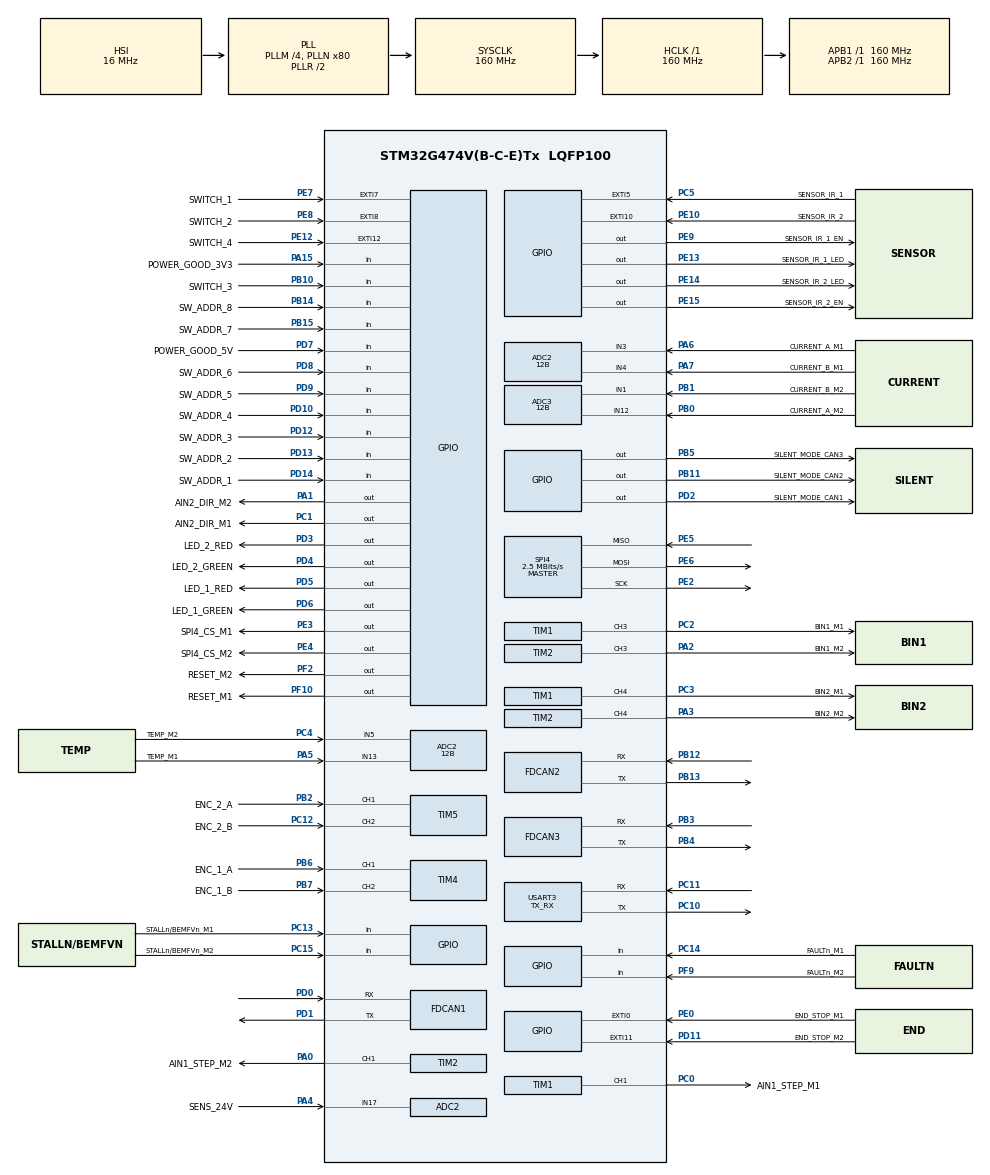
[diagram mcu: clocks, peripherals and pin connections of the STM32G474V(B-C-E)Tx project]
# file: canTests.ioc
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ADC2.Channel-0\#ChannelRegularConversion=ADC_CHANNEL_5
ADC2.Channel-1\#ChannelRegularConversion=ADC_CHANNEL_3
ADC2.Channel-IN13=ADC_CHANNEL_13
ADC2.Channel-IN17=ADC_CHANNEL_17
ADC2.Channel-IN3=ADC_CHANNEL_3
ADC2.Channel-IN5=ADC_CHANNEL_5
ADC2.ClockPrescaler=ADC_CLOCK_ASYNC_DIV1
ADC2.ContinuousConvMode=DISABLE
ADC2.DMAContinuousRequests=DISABLE
ADC2.DataAlign=ADC_DATAALIGN_RIGHT
ADC2.DiscontinuousConvMode=DISABLE
ADC2.EOCSelection=ADC_EOC_SINGLE_CONV
ADC2.EnableAnalogWatchDog1=false
ADC2.EnableAnalogWatchDog2=false
ADC2.EnableAnalogWatchDog3=false
ADC2.EnableInjectedConversion=DISABLE
ADC2.EnableRegularConversion=ENABLE
ADC2.ExternalTrigConv=ADC_SOFTWARE_START
ADC2.ExternalTrigConvEdge=ADC_EXTERNALTRIGCONVEDGE_NONE
ADC2.GainCompensation=0
ADC2.LowPowerAutoWait=DISABLE
ADC2.Mode=ADC_MODE_INDEPENDENT
ADC2.NbrOfConversion=1
ADC2.NbrOfConversionFlag=1
ADC2.OffsetNumber-0\#ChannelRegularConversion=ADC_OFFSET_NONE
ADC2.OffsetNumber-1\#ChannelRegularConversion=ADC_OFFSET_NONE
ADC2.Overrun=ADC_OVR_DATA_PRESERVED
ADC2.OversamplingMode=DISABLE
ADC2.Rank-0\#ChannelRegularConversion=1
ADC2.Rank-1\#ChannelRegularConversion=1
ADC2.Resolution=ADC_RESOLUTION_12B
ADC2.SamplingTime-0\#ChannelRegularConversion=ADC_SAMPLETIME_2CYCLES_5
ADC2.SamplingTime-1\#ChannelRegularConversion=ADC_SAMPLETIME_2CYCLES_5
ADC2.ScanConvMode=ADC_SCAN_DISABLE
ADC2.SingleDiff-1\#ChannelRegularConversion=ADC_DIFFERENTIAL_ENDED
ADC3.Channel-0\#ChannelRegularConversion=ADC_CHANNEL_1
ADC3.Channel-1\#ChannelRegularConversion=ADC_CHANNEL_1
ADC3.ClockPrescaler=ADC_CLOCK_ASYNC_DIV1
ADC3.ContinuousConvMode=DISABLE
ADC3.DMAContinuousRequests=DISABLE
ADC3.DataAlign=ADC_DATAALIGN_RIGHT
ADC3.DiscontinuousConvMode=DISABLE
ADC3.EOCSelection=ADC_EOC_SINGLE_CONV
ADC3.EnableAnalogWatchDog1=false
ADC3.EnableAnalogWatchDog2=false
ADC3.EnableAnalogWatchDog3=false
ADC3.EnableInjectedConversion=DISABLE
ADC3.EnableRegularConversion=ENABLE
ADC3.ExternalTrigConv=ADC_SOFTWARE_START
ADC3.ExternalTrigConvEdge=ADC_EXTERNALTRIGCONVEDGE_NONE
ADC3.GainCompensation=0
ADC3.LowPowerAutoWait=DISABLE
ADC3.Mode=ADC_MODE_INDEPENDENT
ADC3.NbrOfConversion=1
ADC3.NbrOfConversionFlag=1
ADC3.OffsetNumber-0\#ChannelRegularConversion=ADC_OFFSET_NONE
ADC3.OffsetNumber-1\#ChannelRegularConversion=ADC_OFFSET_NONE
ADC3.Overrun=ADC_OVR_DATA_PRESERVED
ADC3.OversamplingMode=DISABLE
ADC3.Rank-0\#ChannelRegularConversion=1
ADC3.Rank-1\#ChannelRegularConversion=1
ADC3.Resolution=ADC_RESOLUTION_12B
ADC3.SamplingTime-0\#ChannelRegularConversion=ADC_SAMPLETIME_2CYCLES_5
ADC3.SamplingTime-1\#ChannelRegularConversion=ADC_SAMPLETIME_2CYCLES_5
ADC3.ScanConvMode=ADC_SCAN_DISABLE
ADC3.master=1
FDCAN1.AutoRetransmission=ENABLE
FDCAN1.ClockDivider=FDCAN_CLOCK_DIV2
FDCAN1.DataPrescaler=2
FDCAN1.DataSyncJumpWidth=4
FDCAN1.DataTimeSeg1=5
FDCAN1.DataTimeSeg2=4
FDCAN1.ExtFiltersNbr=0
FDCAN1.FrameFormat=FDCAN_FRAME_FD_NO_BRS
FDCAN1.Mode=FDCAN_MODE_NORMAL
FDCAN1.NominalPrescaler=2
FDCAN1.NominalSyncJumpWidth=16
FDCAN1.NominalTimeSeg1=63
FDCAN1.NominalTimeSeg2=16
FDCAN1.ProtocolException=DISABLE
FDCAN1.StdFiltersNbr=1
FDCAN1.TransmitPause=ENABLE
FDCAN1.TxFifoQueueMode=FDCAN_TX_FIFO_OPERATION
FDCAN2.AutoRetransmission=ENABLE
FDCAN2.DataPrescaler=1
FDCAN2.DataSyncJumpWidth=4
FDCAN2.DataTimeSeg1=5
FDCAN2.DataTimeSeg2=4
FDCAN2.ExtFiltersNbr=0
FDCAN2.FrameFormat=FDCAN_FRAME_FD_NO_BRS
FDCAN2.Mode=FDCAN_MODE_NORMAL
FDCAN2.NominalPrescaler=1
FDCAN2.NominalSyncJumpWidth=16
FDCAN2.NominalTimeSeg1=63
FDCAN2.NominalTimeSeg2=16
FDCAN2.ProtocolException=DISABLE
FDCAN2.StdFiltersNbr=1
FDCAN2.TransmitPause=ENABLE
FDCAN2.TxFifoQueueMode=FDCAN_TX_FIFO_OPERATION
FDCAN3.AutoRetransmission=ENABLE
FDCAN3.DataPrescaler=1
FDCAN3.DataSyncJumpWidth=4
FDCAN3.DataTimeSeg1=5
FDCAN3.DataTimeSeg2=4
FDCAN3.ExtFiltersNbr=0
FDCAN3.FrameFormat=FDCAN_FRAME_FD_NO_BRS
FDCAN3.Mode=FDCAN_MODE_NORMAL
FDCAN3.NominalPrescaler=1
FDCAN3.NominalSyncJumpWidth=16
FDCAN3.NominalTimeSeg1=63
FDCAN3.NominalTimeSeg2=16
FDCAN3.ProtocolException=DISABLE
FDCAN3.StdFiltersNbr=1
FDCAN3.TransmitPause=ENABLE
FDCAN3.TxFifoQueueMode=FDCAN_TX_FIFO_OPERATION
Mcu.Family=STM32G4
Mcu.Name=STM32G474V(B-C-E)Tx
Mcu.Package=LQFP100
Mcu.UserConstants=APB1_TIMER_CLOCK_FREQUENCY,160000000;CONSOLE_BAUDERATE,115200;SCHEDULER_TIM_PRESCALER,APB1_TIMER_CLOCK_FREQUENCY/1000000;SCHEDULER_TIM_COUNTER_PERIOD,100;ADC_SAMPLING_TIM_PRESCALER,68;ADC_SAMPLING_TIM_COUNTER_PERIOD,100;MOTOR_PWM_TIM_PRESCALER,APB1_TIMER_CLOCK_FREQUENCY/100000;MOTOR_PWM_TIM_COUNTER_PERIOD,100;MOTOR_ACCEL_TIM_PRESCALER,APB1_TIMER_CLOCK_FREQUENCY/100000;MOTOR_ACCEL_TIM_COUNTER_PERIOD,10;MOTOR_ENCODER_TIM_PRESCALER,2;MOTOR_ENCODER_TIM_COUNTER_PERIOD,65534;TEC_TIM_PRESCALER,79;TEC_TIM_COUNTER_PERIOD,65534;FAIL,0;OK,1;FALSE,0;TRUE,1
NVIC.ADC1_2_IRQn=true\:0\:0\:false\:false\:true\:true\:true
NVIC.EXTI0_IRQn=true\:0\:0\:false\:false\:true\:true\:true
NVIC.EXTI15_10_IRQn=true\:0\:0\:false\:false\:true\:true\:true
NVIC.EXTI9_5_IRQn=true\:0\:0\:false\:false\:true\:true\:true
NVIC.PriorityGroup=NVIC_PRIORITYGROUP_4
NVIC.TIM1_BRK_TIM15_IRQn=true\:0\:0\:false\:false\:true\:true\:true
NVIC.TIM1_UP_TIM16_IRQn=true\:0\:0\:false\:false\:true\:true\:true
NVIC.TIM2_IRQn=true\:0\:0\:false\:false\:true\:true\:true
NVIC.TIM3_IRQn=true\:0\:0\:false\:false\:true\:true\:true
NVIC.TIM4_IRQn=true\:0\:0\:false\:false\:true\:true\:true
NVIC.TIM6_DAC_IRQn=true\:0\:0\:false\:false\:true\:true\:true
NVIC.TIM7_DAC_IRQn=true\:0\:0\:false\:false\:true\:true\:true
NVIC.USART3_IRQn=true\:0\:0\:false\:false\:true\:true\:true
PA0.GPIO_Label=AIN1_STEP_M2
PA0.Signal=S_TIM2_CH1
PA1.GPIO_Label=AIN2_DIR_M2
PA1.Signal=GPIO_Output
PA13.Mode=Serial_Wire
PA13.Signal=SYS_JTMS-SWDIO
PA14.Mode=Serial_Wire
PA14.Signal=SYS_JTCK-SWCLK
PA15.GPIO_Label=POWER_GOOD_3V3
PA15.Signal=GPIO_Input
PA2.GPIO_Label=BIN1_M2
PA2.Signal=S_TIM2_CH3
PA3.GPIO_Label=BIN2_M2
PA3.Signal=S_TIM2_CH4
PA4.GPIO_Label=SENS_24V
PA4.Mode=IN17-Single-Ended
PA4.Signal=ADC2_IN17
PA5.GPIO_Label=TEMP_M1
PA5.Mode=IN13-Single-Ended
PA5.Signal=ADC2_IN13
PA6.GPIO_Label=CURRENT_A_M1
PA6.Mode=IN3-Differential
PA6.Signal=ADC2_IN3
PA7.GPIO_Label=CURRENT_B_M1
PA7.Mode=IN3-Differential
PA7.Signal=ADC2_IN4
PB0.GPIO_Label=CURRENT_A_M2
PB0.Mode=IN12-Single-Ended
PB0.Signal=ADC3_IN12
PB1.GPIO_Label=CURRENT_B_M2
PB1.Mode=IN1-Single-Ended
PB1.Signal=ADC3_IN1
PB10.GPIO_Label=SWITCH_3
PB10.Signal=GPIO_Input
PB11.GPIO_Label=SILENT_MODE_CAN2
PB11.Signal=GPIO_Output
PB12.Mode=FDCANFD
PB12.Signal=FDCAN2_RX
PB13.Mode=FDCANFD
PB13.Signal=FDCAN2_TX
PB14.GPIO_Label=SW_ADDR_8
PB14.GPIO_PuPd=GPIO_PULLDOWN
PB14.Signal=GPIO_Input
PB15.GPIO_Label=SW_ADDR_7
PB15.GPIO_PuPd=GPIO_PULLDOWN
PB15.Signal=GPIO_Input
PB2.GPIO_Label=ENC_2_A
PB2.GPIO_PuPd=GPIO_PULLUP
PB2.Signal=S_TIM5_CH1
PB3.Mode=FDCANFD
PB3.Signal=FDCAN3_RX
PB4.Mode=FDCANFD
PB4.Signal=FDCAN3_TX
PB5.GPIO_Label=SILENT_MODE_CAN3
PB5.Signal=GPIO_Output
PB6.GPIO_FM6=SYSCFG_FASTMODEPLUS_PB6
PB6.GPIO_Label=ENC_1_A
PB6.GPIO_PuPd=GPIO_PULLUP
PB6.GPIO_Speed=GPIO_SPEED_FREQ_VERY_HIGH
PB6.Signal=S_TIM4_CH1
PB7.GPIO_FM7=SYSCFG_FASTMODEPLUS_PB7
PB7.GPIO_Label=ENC_1_B
PB7.GPIO_PuPd=GPIO_PULLUP
PB7.GPIO_Speed=GPIO_SPEED_FREQ_VERY_HIGH
PB7.Signal=S_TIM4_CH2
PC0.GPIO_Label=AIN1_STEP_M1
PC0.Signal=S_TIM1_CH1
PC1.GPIO_Label=AIN2_DIR_M1
PC1.Signal=GPIO_Output
PC10.Mode=Asynchronous
PC10.Signal=USART3_TX
PC11.Mode=Asynchronous
PC11.Signal=USART3_RX
PC12.GPIO_Label=ENC_2_B
PC12.GPIO_PuPd=GPIO_PULLUP
PC12.Signal=S_TIM5_CH2
PC13.GPIO_Label=STALLn/BEMFVn_M1
PC13.Signal=GPIO_Input
PC14-OSC32_IN.GPIO_Label=FAULTn_M1
PC14-OSC32_IN.Signal=GPIO_Input
PC15-OSC32_OUT.GPIO_Label=STALLn/BEMFVn_M2
PC15-OSC32_OUT.Signal=GPIO_Input
PC2.GPIO_Label=BIN1_M1
PC2.Signal=S_TIM1_CH3
PC3.GPIO_Label=BIN2_M1
PC3.Signal=S_TIM1_CH4
PC4.GPIO_Label=TEMP_M2
PC4.Mode=IN5-Single-Ended
PC4.Signal=ADC2_IN5
PC5.GPIO_Label=SENSOR_IR_1
PC5.GPIO_ModeDefaultEXTI=GPIO_MODE_IT_RISING_FALLING
PC5.GPIO_PuPd=GPIO_PULLDOWN
PC5.Signal=GPXTI5
PD0.Mode=FDCANFD
PD0.Signal=FDCAN1_RX
PD1.Mode=FDCANFD
PD1.Signal=FDCAN1_TX
PD10.GPIO_Label=SW_ADDR_4
PD10.GPIO_PuPd=GPIO_PULLDOWN
PD10.Signal=GPIO_Input
PD11.GPIO_Label=END_STOP_M2
PD11.GPIO_ModeDefaultEXTI=GPIO_MODE_IT_FALLING
PD11.Signal=GPXTI11
PD12.GPIO_Label=SW_ADDR_3
PD12.GPIO_PuPd=GPIO_PULLDOWN
PD12.Signal=GPIO_Input
PD13.GPIO_Label=SW_ADDR_2
PD13.GPIO_PuPd=GPIO_PULLDOWN
PD13.Signal=GPIO_Input
PD14.GPIO_Label=SW_ADDR_1
PD14.GPIO_PuPd=GPIO_PULLDOWN
PD14.Signal=GPIO_Input
PD2.GPIO_Label=SILENT_MODE_CAN1
PD2.Signal=GPIO_Output
PD3.GPIO_Label=LED_2_RED
PD3.Signal=GPIO_Output
PD4.GPIO_Label=LED_2_GREEN
PD4.Signal=GPIO_Output
PD5.GPIO_Label=LED_1_RED
PD5.Signal=GPIO_Output
PD6.GPIO_Label=LED_1_GREEN
PD6.Signal=GPIO_Output
PD7.GPIO_Label=POWER_GOOD_5V
PD7.Signal=GPIO_Input
PD8.GPIO_Label=SW_ADDR_6
PD8.GPIO_PuPd=GPIO_PULLDOWN
PD8.Signal=GPIO_Input
PD9.GPIO_Label=SW_ADDR_5
PD9.GPIO_PuPd=GPIO_PULLDOWN
PD9.Signal=GPIO_Input
PE0.GPIO_Label=END_STOP_M1
PE0.GPIO_ModeDefaultEXTI=GPIO_MODE_IT_FALLING
PE0.Signal=GPXTI0
PE10.GPIO_Label=SENSOR_IR_2
PE10.GPIO_ModeDefaultEXTI=GPIO_MODE_IT_RISING_FALLING
PE10.GPIO_PuPd=GPIO_PULLDOWN
PE10.Signal=GPXTI10
PE12.GPIO_Label=SWITCH_4
PE12.GPIO_ModeDefaultEXTI=GPIO_MODE_IT_FALLING
PE12.Signal=GPXTI12
PE13.GPIO_Label=SENSOR_IR_1_LED
PE13.Signal=GPIO_Output
PE14.GPIO_Label=SENSOR_IR_2_LED
PE14.Signal=GPIO_Output
PE15.GPIO_Label=SENSOR_IR_2_EN
PE15.Signal=GPIO_Output
PE2.Mode=Full_Duplex_Master
PE2.Signal=SPI4_SCK
PE3.GPIO_Label=SPI4_CS_M1
PE3.Signal=GPIO_Output
PE4.GPIO_Label=SPI4_CS_M2
PE4.Signal=GPIO_Output
PE5.Mode=Full_Duplex_Master
PE5.Signal=SPI4_MISO
PE6.Mode=Full_Duplex_Master
PE6.Signal=SPI4_MOSI
PE7.GPIO_Label=SWITCH_1
PE7.GPIO_ModeDefaultEXTI=GPIO_MODE_IT_FALLING
PE7.Signal=GPXTI7
PE8.GPIO_Label=SWITCH_2
PE8.GPIO_ModeDefaultEXTI=GPIO_MODE_IT_FALLING
PE8.Signal=GPXTI8
PE9.GPIO_Label=SENSOR_IR_1_EN
PE9.Signal=GPIO_Output
PF0-OSC_IN.Mode=HSE-External-Oscillator
PF0-OSC_IN.Signal=RCC_OSC_IN
PF1-OSC_OUT.Mode=HSE-External-Oscillator
PF1-OSC_OUT.Signal=RCC_OSC_OUT
PF10.GPIO_Label=RESET_M1
PF10.Signal=GPIO_Output
PF2.GPIO_Label=RESET_M2
PF2.Signal=GPIO_Output
PF9.GPIO_Label=FAULTn_M2
PF9.Signal=GPIO_Input
ProjectManager.HeapSize=0x200
ProjectManager.StackSize=0x400
ProjectManager.TargetToolchain=STM32CubeIDE
RCC.ADC12Freq_Value=160000000
RCC.ADC345Freq_Value=160000000
RCC.AHBFreq_Value=160000000
RCC.APB1Freq_Value=160000000
RCC.APB1TimFreq_Value=160000000
RCC.APB2Freq_Value=160000000
RCC.APB2TimFreq_Value=160000000
RCC.CK48CLockSelection=RCC_USBCLKSOURCE_HSI48
RCC.CortexFreq_Value=160000000
RCC.EXTERNAL_CLOCK_VALUE=12288000
RCC.HCLKFreq_Value=160000000
RCC.HSE_VALUE=16000000
RCC.HSI48_VALUE=48000000
RCC.HSI_VALUE=16000000
RCC.LSE_VALUE=32768
RCC.PLLM=RCC_PLLM_DIV4
RCC.PLLN=80
RCC.SYSCLKFreq_VALUE=160000000
RCC.SYSCLKSource=RCC_SYSCLKSOURCE_PLLCLK
RCC.USBFreq_Value=48000000
RCC.VCOOutputFreq_Value=320000000
SH.S_TIM1_CH1.0=TIM1_CH1,PWM Generation1 CH1
SH.S_TIM1_CH3.0=TIM1_CH3,PWM Generation3 CH3
SH.S_TIM1_CH4.0=TIM1_CH4,PWM Generation4 CH4
SH.S_TIM2_CH1.0=TIM2_CH1,PWM Generation1 CH1
SH.S_TIM2_CH3.0=TIM2_CH3,PWM Generation3 CH3
SH.S_TIM2_CH4.0=TIM2_CH4,PWM Generation4 CH4
SH.S_TIM4_CH1.0=TIM4_CH1,Encoder_Interface
SH.S_TIM4_CH2.0=TIM4_CH2,Encoder_Interface
SH.S_TIM5_CH1.0=TIM5_CH1,Encoder_Interface
SH.S_TIM5_CH2.0=TIM5_CH2,Encoder_Interface
SPI4.BaudRatePrescaler=SPI_BAUDRATEPRESCALER_64
SPI4.CLKPhase=SPI_PHASE_1EDGE
SPI4.CLKPolarity=SPI_POLARITY_LOW
SPI4.CRCCalculation=SPI_CRCCALCULATION_DISABLE
SPI4.CalculateBaudRate=2.5 MBits/s
SPI4.DataSize=SPI_DATASIZE_16BIT
SPI4.Direction=SPI_DIRECTION_2LINES
SPI4.FirstBit=SPI_FIRSTBIT_MSB
SPI4.Mode=SPI_MODE_MASTER
SPI4.NSS=SPI_NSS_SOFT
SPI4.NSSPMode=SPI_NSS_PULSE_ENABLE
SPI4.TIMode=SPI_TIMODE_DISABLE
SPI4.VirtualType=VM_MASTER
TIM1.AutoReloadPreload=TIM_AUTORELOAD_PRELOAD_ENABLE
TIM1.AutomaticOutput=TIM_AUTOMATICOUTPUT_DISABLE
TIM1.Break2Filter=0
TIM1.Break2Polarity=TIM_BREAK2POLARITY_HIGH
TIM1.Break2State=TIM_BREAK2_DISABLE
TIM1.BreakFilter=0
TIM1.BreakPolarity=TIM_BREAKPOLARITY_HIGH
TIM1.BreakState=TIM_BREAK_DISABLE
TIM1.Channel-PWM\ Generation1\ CH1=TIM_CHANNEL_1
TIM1.Channel-PWM\ Generation3\ CH3=TIM_CHANNEL_3
TIM1.Channel-PWM\ Generation4\ CH4=TIM_CHANNEL_4
TIM1.ClearInputSource=TIM_CLEARINPUTSOURCE_NONE
TIM1.ClockDivision=TIM_CLOCKDIVISION_DIV1
TIM1.CounterMode=TIM_COUNTERMODE_UP
TIM1.Dithering=Disable
TIM1.LockLevel=TIM_LOCKLEVEL_OFF
TIM1.OCFastMode_PWM-PWM\ Generation1\ CH1=TIM_OCFAST_ENABLE
TIM1.OCFastMode_PWM-PWM\ Generation3\ CH3=TIM_OCFAST_ENABLE
TIM1.OCFastMode_PWM-PWM\ Generation4\ CH4=TIM_OCFAST_ENABLE
TIM1.OCIdleState_1=TIM_OCIDLESTATE_RESET
TIM1.OCIdleState_3=TIM_OCIDLESTATE_RESET
TIM1.OCIdleState_4=TIM_OCIDLESTATE_RESET
TIM1.OCMode_PWM-PWM\ Generation1\ CH1=TIM_OCMODE_PWM1
TIM1.OCMode_PWM-PWM\ Generation3\ CH3=TIM_OCMODE_PWM1
TIM1.OCMode_PWM-PWM\ Generation4\ CH4=TIM_OCMODE_PWM1
TIM1.OCPolarity_1=TIM_OCPOLARITY_HIGH
TIM1.OCPolarity_3=TIM_OCPOLARITY_HIGH
TIM1.OCPolarity_4=TIM_OCPOLARITY_HIGH
TIM1.OffStateIDLEMode=TIM_OSSI_DISABLE
TIM1.OffStateRunMode=TIM_OSSR_DISABLE
TIM1.PeriodNoDither=MOTOR_PWM_TIM_COUNTER_PERIOD
TIM1.Prescaler=MOTOR_PWM_TIM_PRESCALER
TIM1.PulseNoDither_1=0
TIM1.PulseNoDither_3=0
TIM1.PulseNoDither_4=0
TIM1.RepetitionCounter=0
TIM1.SourceBRK2COMP1=TIM_BREAKINPUTSOURCE_DISABLE
TIM1.SourceBRK2COMP2=TIM_BREAKINPUTSOURCE_DISABLE
TIM1.SourceBRK2COMP3=TIM_BREAKINPUTSOURCE_DISABLE
TIM1.SourceBRK2COMP4=TIM_BREAKINPUTSOURCE_DISABLE
TIM1.SourceBRK2COMP5=TIM_BREAKINPUTSOURCE_DISABLE
TIM1.SourceBRK2COMP6=TIM_BREAKINPUTSOURCE_DISABLE
TIM1.SourceBRK2COMP7=TIM_BREAKINPUTSOURCE_DISABLE
TIM1.SourceBRK2DigInput=TIM_BREAKINPUTSOURCE_DISABLE
TIM1.SourceBRKCOMP1=TIM_BREAKINPUTSOURCE_DISABLE
TIM1.SourceBRKCOMP2=TIM_BREAKINPUTSOURCE_DISABLE
TIM1.SourceBRKCOMP3=TIM_BREAKINPUTSOURCE_DISABLE
TIM1.SourceBRKCOMP4=TIM_BREAKINPUTSOURCE_DISABLE
TIM1.SourceBRKCOMP5=TIM_BREAKINPUTSOURCE_DISABLE
TIM1.SourceBRKCOMP6=TIM_BREAKINPUTSOURCE_DISABLE
TIM1.SourceBRKCOMP7=TIM_BREAKINPUTSOURCE_DISABLE
TIM1.SourceBRKDigInput=TIM_BREAKINPUTSOURCE_DISABLE
TIM1.TIM_MasterOutputTrigger=TIM_TRGO_RESET
TIM1.TIM_MasterOutputTrigger2=TIM_TRGO2_RESET
TIM1.TIM_MasterSlaveMode=TIM_MASTERSLAVEMODE_DISABLE
TIM15.PeriodNoDither=SCHEDULER_TIM_COUNTER_PERIOD-1
TIM15.Prescaler=SCHEDULER_TIM_PRESCALER-1
TIM2.AutoReloadPreload=TIM_AUTORELOAD_PRELOAD_ENABLE
TIM2.Channel-PWM\ Generation1\ CH1=TIM_CHANNEL_1
TIM2.Channel-PWM\ Generation3\ CH3=TIM_CHANNEL_3
TIM2.Channel-PWM\ Generation4\ CH4=TIM_CHANNEL_4
TIM2.ClearInputSource=TIM_CLEARINPUTSOURCE_NONE
TIM2.ClockDivision=TIM_CLOCKDIVISION_DIV1
TIM2.CounterMode=TIM_COUNTERMODE_UP
TIM2.Dithering=Disable
TIM2.OCFastMode_PWM-PWM\ Generation1\ CH1=TIM_OCFAST_DISABLE
TIM2.OCFastMode_PWM-PWM\ Generation3\ CH3=TIM_OCFAST_ENABLE
TIM2.OCFastMode_PWM-PWM\ Generation4\ CH4=TIM_OCFAST_ENABLE
TIM2.OCMode_PWM-PWM\ Generation1\ CH1=TIM_OCMODE_PWM1
TIM2.OCMode_PWM-PWM\ Generation3\ CH3=TIM_OCMODE_PWM1
TIM2.OCMode_PWM-PWM\ Generation4\ CH4=TIM_OCMODE_PWM1
TIM2.OCPolarity_1=TIM_OCPOLARITY_HIGH
TIM2.OCPolarity_3=TIM_OCPOLARITY_HIGH
TIM2.OCPolarity_4=TIM_OCPOLARITY_HIGH
TIM2.PeriodNoDither=MOTOR_PWM_TIM_COUNTER_PERIOD
TIM2.Prescaler=MOTOR_PWM_TIM_PRESCALER
TIM2.PulseNoDither_1=0
TIM2.PulseNoDither_3=0
TIM2.PulseNoDither_4=0
TIM2.TIM_MasterOutputTrigger=TIM_TRGO_RESET
TIM2.TIM_MasterSlaveMode=TIM_MASTERSLAVEMODE_DISABLE
TIM20.PeriodNoDither=ADC_SAMPLING_TIM_COUNTER_PERIOD-1
TIM20.Prescaler=ADC_SAMPLING_TIM_PRESCALER-1
TIM20.TIM_MasterOutputTrigger=TIM_TRGO_UPDATE
TIM3.AutoReloadPreload=TIM_AUTORELOAD_PRELOAD_ENABLE
TIM3.Channel-PWM\ Generation1\ No\ Output=TIM_CHANNEL_1
TIM3.OCFastMode_PWM-PWM\ Generation1\ No\ Output=TIM_OCFAST_ENABLE
TIM3.PeriodNoDither=MOTOR_ACCEL_TIM_COUNTER_PERIOD
TIM3.Prescaler=MOTOR_ACCEL_TIM_PRESCALER
TIM3.PulseNoDither_1=5
TIM3.TIM_MasterOutputTrigger=TIM_TRGO_RESET
TIM4.AutoReloadPreload=TIM_AUTORELOAD_PRELOAD_ENABLE
TIM4.ClockDivision=TIM_CLOCKDIVISION_DIV1
TIM4.EncoderMode=TIM_ENCODERMODE_TI12
TIM4.IC1Filter=10
TIM4.IC2Filter=10
TIM4.PeriodNoDither=MOTOR_ENCODER_TIM_COUNTER_PERIOD
TIM4.Prescaler=MOTOR_ENCODER_TIM_PRESCALER-1
TIM4.TIM_MasterOutputTrigger=TIM_TRGO_UPDATE
TIM4.TIM_MasterSlaveMode=TIM_MASTERSLAVEMODE_DISABLE
TIM5.AutoReloadPreload=TIM_AUTORELOAD_PRELOAD_ENABLE
TIM5.EncoderMode=TIM_ENCODERMODE_TI12
TIM5.PeriodNoDither=MOTOR_ENCODER_TIM_COUNTER_PERIOD
TIM5.Prescaler=MOTOR_ENCODER_TIM_PRESCALER-1
TIM5.TIM_MasterOutputTrigger=TIM_TRGO_UPDATE
USART3.AutoBaudRateEnableParam=UART_ADVFEATURE_AUTOBAUDRATE_DISABLE
USART3.BaudRate=CONSOLE_BAUDERATE
USART3.ClockPrescaler=PRESCALER_DIV1
USART3.DMADisableonRxErrorParam=ADVFEATURE_DMA_ENABLEONRXERROR
USART3.DataInvertParam=ADVFEATURE_DATAINV_DISABLE
USART3.FIFOMode=FIFOMODE_DISABLE
USART3.MSBFirstParam=ADVFEATURE_MSBFIRST_DISABLE
USART3.Mode=MODE_TX_RX
USART3.OneBitSampling=UART_ONE_BIT_SAMPLE_DISABLE
USART3.OverSampling=UART_OVERSAMPLING_16
USART3.OverrunDisableParam=ADVFEATURE_OVERRUN_ENABLE
USART3.Parity=PARITY_NONE
USART3.RXFIFOThreshold=RXFIFO_THRESHOLD_1EIGHTHFULL
USART3.RxPinLevelInvertParam=ADVFEATURE_RXINV_DISABLE
USART3.StopBits=STOPBITS_1
USART3.SwapParam=ADVFEATURE_SWAP_DISABLE
USART3.TXFIFOThreshold=TXFIFO_THRESHOLD_1EIGHTHFULL
USART3.TxPinLevelInvertParam=ADVFEATURE_TXINV_DISABLE
USART3.VirtualMode-Asynchronous=VM_ASYNC
USART3.WordLength=WORDLENGTH_8B
VP_SYS_VS_DBSignals.Mode=DisableDeadBatterySignals
VP_TIM15_VS_ClockSourceINT.Mode=Internal
VP_TIM1_VS_ClockSourceINT.Mode=Internal
VP_TIM20_VS_ClockSourceINT.Mode=Internal
VP_TIM2_VS_ClockSourceINT.Mode=Internal
VP_TIM3_VS_ClockSourceINT.Mode=Internal
VP_TIM3_VS_no_output1.Mode=PWM Generation1 No Output
VP_TIM4_VS_OPM.Mode=OPM_bit
VP_TIM5_VS_OPM.Mode=OPM_bit
VP_TIM6_VS_ClockSourceINT.Mode=Enable_Timer
VP_TIM7_VS_ClockSourceINT.Mode=Enable_Timer
board=custom

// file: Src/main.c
/* USER CODE BEGIN Header */
/**
  ******************************************************************************
  * @file           : main.c
  * @brief          : Main program body
  ******************************************************************************
  * @attention
  *
  * <h2><center>&copy; Copyright (c) 2020 STMicroelectronics.
  * All rights reserved.</center></h2>
  *
  * This software component is licensed by ST under BSD 3-Clause license,
  * the "License"; You may not use this file except in compliance with the
  * License. You may obtain a copy of the License at:
  *                        opensource.org/licenses/BSD-3-Clause
  *
  ******************************************************************************
  */
/* USER CODE END Header */

#include "main.h"
#include "adc.h"
#include "fdcan.h"
#include "spi.h"
#include "tim.h"
#include "usart.h"
#include "gpio.h"

/* USER CODE BEGIN Includes */
#include "canTests_main.h"
/* USER CODE END Includes */

void SystemClock_Config(void);

int main(void)
{

  /* MCU Configuration--------------------------------------------------------*/

  /* Reset of all peripherals, Initializes the Flash interface and the Systick. */
  HAL_Init();

  /* Configure the system clock */
  SystemClock_Config();

  /* Initialize all configured peripherals */
  MX_GPIO_Init();
  MX_ADC2_Init();
  MX_ADC3_Init();
  MX_FDCAN1_Init();
  MX_FDCAN2_Init();
  MX_FDCAN3_Init();
  MX_SPI4_Init();
  MX_TIM1_Init();
  MX_TIM2_Init();
  MX_TIM4_Init();
  MX_USART3_UART_Init();
  MX_TIM6_Init();
  MX_TIM7_Init();
  MX_TIM15_Init();
  MX_TIM20_Init();
  MX_TIM3_Init();
  MX_TIM5_Init();
  /* USER CODE BEGIN 2 */
  canTests_main();
  /* USER CODE END 2 */

  /* Infinite loop */
  while (1)
  {

  }
}

void SystemClock_Config(void)
{
  RCC_OscInitTypeDef RCC_OscInitStruct = {0};
  RCC_ClkInitTypeDef RCC_ClkInitStruct = {0};
  RCC_PeriphCLKInitTypeDef PeriphClkInit = {0};

  /** Configure the main internal regulator output voltage
  */
  HAL_PWREx_ControlVoltageScaling(PWR_REGULATOR_VOLTAGE_SCALE1_BOOST);
  /** Initializes the CPU, AHB and APB busses clocks
  */
  RCC_OscInitStruct.OscillatorType = RCC_OSCILLATORTYPE_HSI;
  RCC_OscInitStruct.HSIState = RCC_HSI_ON;
  RCC_OscInitStruct.HSICalibrationValue = RCC_HSICALIBRATION_DEFAULT;
  RCC_OscInitStruct.PLL.PLLState = RCC_PLL_ON;
  RCC_OscInitStruct.PLL.PLLSource = RCC_PLLSOURCE_HSI;
  RCC_OscInitStruct.PLL.PLLM = RCC_PLLM_DIV4;
  RCC_OscInitStruct.PLL.PLLN = 80;
  RCC_OscInitStruct.PLL.PLLP = RCC_PLLP_DIV2;
  RCC_OscInitStruct.PLL.PLLQ = RCC_PLLQ_DIV2;
  RCC_OscInitStruct.PLL.PLLR = RCC_PLLR_DIV2;
  if (HAL_RCC_OscConfig(&RCC_OscInitStruct) != HAL_OK)
  {
    Error_Handler();
  }
  /** Initializes the CPU, AHB and APB busses clocks
  */
  RCC_ClkInitStruct.ClockType = RCC_CLOCKTYPE_HCLK|RCC_CLOCKTYPE_SYSCLK
                              |RCC_CLOCKTYPE_PCLK1|RCC_CLOCKTYPE_PCLK2;
  RCC_ClkInitStruct.SYSCLKSource = RCC_SYSCLKSOURCE_PLLCLK;
  RCC_ClkInitStruct.AHBCLKDivider = RCC_SYSCLK_DIV1;
  RCC_ClkInitStruct.APB1CLKDivider = RCC_HCLK_DIV1;
  RCC_ClkInitStruct.APB2CLKDivider = RCC_HCLK_DIV1;

  if (HAL_RCC_ClockConfig(&RCC_ClkInitStruct, FLASH_LATENCY_7) != HAL_OK)
  {
    Error_Handler();
  }
  /** Initializes the peripherals clocks
  */
  PeriphClkInit.PeriphClockSelection = RCC_PERIPHCLK_USART3|RCC_PERIPHCLK_ADC12
                              |RCC_PERIPHCLK_ADC345|RCC_PERIPHCLK_FDCAN;
  PeriphClkInit.Usart3ClockSelection = RCC_USART3CLKSOURCE_PCLK1;
  PeriphClkInit.FdcanClockSelection = RCC_FDCANCLKSOURCE_PCLK1;
  PeriphClkInit.Adc12ClockSelection = RCC_ADC12CLKSOURCE_SYSCLK;
  PeriphClkInit.Adc345ClockSelection = RCC_ADC345CLKSOURCE_SYSCLK;
  if (HAL_RCCEx_PeriphCLKConfig(&PeriphClkInit) != HAL_OK)
  {
    Error_Handler();
  }
}

void Error_Handler(void)
{
}

/************************ (C) COPYRIGHT STMicroelectronics *****END OF FILE****/
